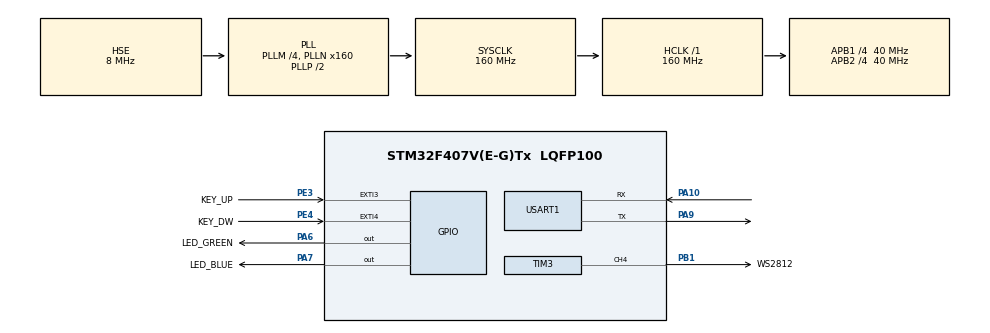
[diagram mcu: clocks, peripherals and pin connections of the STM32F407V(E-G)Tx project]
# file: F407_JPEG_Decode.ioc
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Dma.Request0=TIM3_CH4/UP
Dma.TIM3_CH4/UP.0.Direction=DMA_MEMORY_TO_PERIPH
Dma.TIM3_CH4/UP.0.FIFOMode=DMA_FIFOMODE_DISABLE
Dma.TIM3_CH4/UP.0.Instance=DMA1_Stream2
Dma.TIM3_CH4/UP.0.MemDataAlignment=DMA_MDATAALIGN_HALFWORD
Dma.TIM3_CH4/UP.0.MemInc=DMA_MINC_ENABLE
Dma.TIM3_CH4/UP.0.Mode=DMA_NORMAL
Dma.TIM3_CH4/UP.0.PeriphDataAlignment=DMA_PDATAALIGN_HALFWORD
Dma.TIM3_CH4/UP.0.PeriphInc=DMA_PINC_DISABLE
Dma.TIM3_CH4/UP.0.Priority=DMA_PRIORITY_MEDIUM
Mcu.Family=STM32F4
Mcu.Name=STM32F407V(E-G)Tx
Mcu.Package=LQFP100
NVIC.DMA1_Stream2_IRQn=true\:0\:0\:false\:false\:true\:false\:true
NVIC.PriorityGroup=NVIC_PRIORITYGROUP_4
NVIC.RTC_WKUP_IRQn=true\:1\:0\:true\:false\:true\:true\:true
PA0-WKUP.Mode=SYS_WakeUp0
PA0-WKUP.Signal=SYS_WKUP
PA10.Mode=Asynchronous
PA10.Signal=USART1_RX
PA13.Mode=Serial_Wire
PA13.Signal=SYS_JTMS-SWDIO
PA14.Mode=Serial_Wire
PA14.Signal=SYS_JTCK-SWCLK
PA6.GPIO_Label=LED_GREEN
PA6.GPIO_ModeDefaultOutputPP=GPIO_MODE_OUTPUT_OD
PA6.PinState=GPIO_PIN_SET
PA6.Signal=GPIO_Output
PA7.GPIO_Label=LED_BLUE
PA7.GPIO_ModeDefaultOutputPP=GPIO_MODE_OUTPUT_PP
PA7.GPIO_PuPd=GPIO_NOPULL
PA7.GPIO_Speed=GPIO_SPEED_FREQ_LOW
PA7.PinState=GPIO_PIN_RESET
PA7.Signal=GPIO_Output
PA9.Mode=Asynchronous
PA9.Signal=USART1_TX
PB1.GPIO_Label=WS2812
PB1.GPIO_PuPd=GPIO_NOPULL
PB1.GPIO_Speed=GPIO_SPEED_FREQ_MEDIUM
PB1.Signal=S_TIM3_CH4
PC14-OSC32_IN.Mode=LSE-External-Oscillator
PC14-OSC32_IN.Signal=RCC_OSC32_IN
PC15-OSC32_OUT.Mode=LSE-External-Oscillator
PC15-OSC32_OUT.Signal=RCC_OSC32_OUT
PE3.GPIO_Label=KEY_UP
PE3.GPIO_ModeDefaultEXTI=GPIO_MODE_IT_RISING
PE3.GPIO_PuPd=GPIO_NOPULL
PE3.Signal=GPXTI3
PE4.GPIO_Label=KEY_DW
PE4.GPIO_ModeDefaultEXTI=GPIO_MODE_IT_RISING
PE4.GPIO_PuPd=GPIO_NOPULL
PE4.Signal=GPXTI4
PH0-OSC_IN.Mode=HSE-External-Oscillator
PH0-OSC_IN.Signal=RCC_OSC_IN
PH1-OSC_OUT.Mode=HSE-External-Oscillator
PH1-OSC_OUT.Signal=RCC_OSC_OUT
ProjectManager.HeapSize=0x1000
ProjectManager.StackSize=0x800
ProjectManager.TargetToolchain=MDK-ARM V5
RCC.48MHZClocksFreq_Value=45714285.71428572
RCC.AHBFreq_Value=160000000
RCC.APB1CLKDivider=RCC_HCLK_DIV4
RCC.APB1Freq_Value=40000000
RCC.APB1TimFreq_Value=80000000
RCC.APB2CLKDivider=RCC_HCLK_DIV4
RCC.APB2Freq_Value=40000000
RCC.APB2TimFreq_Value=80000000
RCC.CortexFreq_Value=160000000
RCC.EnbaleCSS=true
RCC.HCLKFreq_Value=160000000
RCC.HSE_VALUE=8000000
RCC.HSI_VALUE=16000000
RCC.PLLM=4
RCC.PLLN=160
RCC.PLLQ=7
RCC.PLLSourceVirtual=RCC_PLLSOURCE_HSE
RCC.RCC_RTC_Clock_Source=RCC_RTCCLKSOURCE_LSE
RCC.RCC_RTC_Clock_SourceVirtual=RCC_RTCCLKSOURCE_LSE
RCC.RCC_RTC_Clock_Source_FROM_HSE=RCC_RTCCLKSOURCE_HSE_DIV26
RCC.SYSCLKFreq_VALUE=160000000
RCC.SYSCLKSource=RCC_SYSCLKSOURCE_PLLCLK
RCC.VCOOutputFreq_Value=320000000
RTC.WakeUpClock=RTC_WAKEUPCLOCK_CK_SPRE_16BITS
SH.S_TIM3_CH4.0=TIM3_CH4,PWM Generation4 CH4
TIM3.AutoReloadPreload=TIM_AUTORELOAD_PRELOAD_DISABLE
TIM3.Channel-PWM\ Generation4\ CH4=TIM_CHANNEL_4
TIM3.OC4Preload_PWM=DISABLE
TIM3.Period=100-1
TIM3.Pulse-PWM\ Generation4\ CH4=0
USART1.VirtualMode=VM_ASYNC
VP_RTC_VS_RTC_Activate.Mode=RTC_Enabled
VP_RTC_VS_RTC_Calendar.Mode=RTC_Calendar
VP_RTC_VS_RTC_WakeUp_intern.Mode=WakeUp
VP_TIM3_VS_ClockSourceINT.Mode=Internal
board=custom

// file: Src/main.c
/* USER CODE BEGIN Header */
/**
  ******************************************************************************
  * @file           : main.c
  * @brief          : Main program body
  ******************************************************************************
  * @attention
  *
  * <h2><center>&copy; Copyright (c) 2019 STMicroelectronics.
  * All rights reserved.</center></h2>
  *
  * This software component is licensed by ST under Ultimate Liberty license
  * SLA0044, the "License"; You may not use this file except in compliance with
  * the License. You may obtain a copy of the License at:
  *                             www.st.com/SLA0044
  *
  ******************************************************************************
  */
/* USER CODE END Header */

#include "main.h"
#include "dma.h"
#include "rtc.h"
#include "tim.h"
#include "usart.h"
#include "gpio.h"

/* USER CODE BEGIN Includes */
#include "stdio.h"
#include "stdlib.h"
#include "ws2812.h"
/* USER CODE END Includes */

void SystemClock_Config(void);
/* USER CODE BEGIN PFP */

/******************
*	printf 重定向
******************/
int fputc(int ch,FILE* fp)
{
	while(!(huart1.gState == HAL_UART_STATE_READY));
	HAL_UART_Transmit(&huart1,(uint8_t*)&ch,1,10);
	return ch;
}

/* USER CODE END PFP */

int main(void)
{

  /* MCU Configuration--------------------------------------------------------*/

  /* Reset of all peripherals, Initializes the Flash interface and the Systick. */
  HAL_Init();

  /* Configure the system clock */
  SystemClock_Config();

  /* Initialize all configured peripherals */
  MX_GPIO_Init();
  MX_RTC_Init();
  MX_USART1_UART_Init();
  MX_DMA_Init();
  MX_TIM3_Init();
  /* USER CODE BEGIN 2 */

	ws2812_update();

  /* USER CODE END 2 */

  /* Infinite loop */
	while (1)
	{

	}
}

void SystemClock_Config(void)
{
  RCC_OscInitTypeDef RCC_OscInitStruct = {0};
  RCC_ClkInitTypeDef RCC_ClkInitStruct = {0};
  RCC_PeriphCLKInitTypeDef PeriphClkInitStruct = {0};

  /** Configure the main internal regulator output voltage
  */
  __HAL_RCC_PWR_CLK_ENABLE();
  __HAL_PWR_VOLTAGESCALING_CONFIG(PWR_REGULATOR_VOLTAGE_SCALE1);
  /** Initializes the CPU, AHB and APB busses clocks
  */
  RCC_OscInitStruct.OscillatorType = RCC_OSCILLATORTYPE_HSE|RCC_OSCILLATORTYPE_LSE;
  RCC_OscInitStruct.HSEState = RCC_HSE_ON;
  RCC_OscInitStruct.LSEState = RCC_LSE_ON;
  RCC_OscInitStruct.PLL.PLLState = RCC_PLL_ON;
  RCC_OscInitStruct.PLL.PLLSource = RCC_PLLSOURCE_HSE;
  RCC_OscInitStruct.PLL.PLLM = 4;
  RCC_OscInitStruct.PLL.PLLN = 160;
  RCC_OscInitStruct.PLL.PLLP = RCC_PLLP_DIV2;
  RCC_OscInitStruct.PLL.PLLQ = 7;
  if (HAL_RCC_OscConfig(&RCC_OscInitStruct) != HAL_OK)
  {
    Error_Handler();
  }
  /** Initializes the CPU, AHB and APB busses clocks
  */
  RCC_ClkInitStruct.ClockType = RCC_CLOCKTYPE_HCLK|RCC_CLOCKTYPE_SYSCLK
                              |RCC_CLOCKTYPE_PCLK1|RCC_CLOCKTYPE_PCLK2;
  RCC_ClkInitStruct.SYSCLKSource = RCC_SYSCLKSOURCE_PLLCLK;
  RCC_ClkInitStruct.AHBCLKDivider = RCC_SYSCLK_DIV1;
  RCC_ClkInitStruct.APB1CLKDivider = RCC_HCLK_DIV4;
  RCC_ClkInitStruct.APB2CLKDivider = RCC_HCLK_DIV4;

  if (HAL_RCC_ClockConfig(&RCC_ClkInitStruct, FLASH_LATENCY_5) != HAL_OK)
  {
    Error_Handler();
  }
  PeriphClkInitStruct.PeriphClockSelection = RCC_PERIPHCLK_RTC;
  PeriphClkInitStruct.RTCClockSelection = RCC_RTCCLKSOURCE_LSE;
  if (HAL_RCCEx_PeriphCLKConfig(&PeriphClkInitStruct) != HAL_OK)
  {
    Error_Handler();
  }
  /** Enables the Clock Security System
  */
  HAL_RCC_EnableCSS();
}

void Error_Handler(void)
{
  /* USER CODE BEGIN Error_Handler_Debug */
  /* User can add his own implementation to report the HAL error return state */
	while(1)
	{
		HAL_GPIO_TogglePin(LED_GREEN_GPIO_Port,LED_GREEN_Pin);
		HAL_Delay(100);
	}
  /* USER CODE END Error_Handler_Debug */
}

/************************ (C) COPYRIGHT STMicroelectronics *****END OF FILE****/
